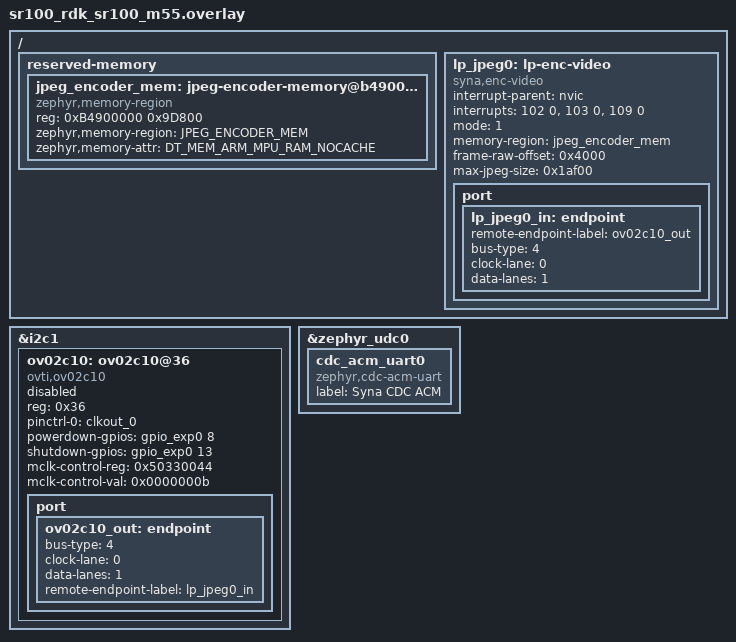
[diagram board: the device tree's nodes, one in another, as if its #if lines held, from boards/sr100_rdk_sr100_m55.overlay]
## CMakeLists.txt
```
cmake_minimum_required(VERSION 3.20.0)
find_package(Zephyr REQUIRED HINTS $ENV{ZEPHYR_BASE})
project(camera_usb_stream)

# Pulls in the Zephyr sample_usbd helper (sample_usbd.h/.c), reused verbatim
# from the SDK's mipi_capture_to_enc sample instead of hand-rolling USB
# device-stack bring-up.
include(${ZEPHYR_BASE}/samples/subsys/usb/common/common.cmake)

target_sources(app PRIVATE
	src/main.c
	src/usb_cdc_transport.c
)
```

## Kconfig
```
mainmenu "USB CDC Camera Streaming Lab (SR110 Lab C5)"

source "Kconfig.zephyr"

# Reuses Zephyr's shared "sample_usbd" helper Kconfig (device descriptors,
# VID/PID, etc.) - same mechanism the SDK's mipi_capture_to_enc sample uses.
source "samples/subsys/usb/common/Kconfig.sample_usbd"

config SAMPLE_USBD_PRODUCT
	default "SR110_Camera_Stream"

config SAMPLE_USBD_PID
	default 0x0009

menu "USB Camera Streaming Lab"

endmenu
```

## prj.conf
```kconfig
CONFIG_CONSOLE=y
CONFIG_PRINTK=y
CONFIG_LOG=y
CONFIG_LOG_MODE_IMMEDIATE=y
# Avoid Kconfig warnings from board defaults pulling in I2C shell options.
CONFIG_I2C_SHELL=n
CONFIG_FPU=y
CONFIG_I2C=y
CONFIG_GPIO=y
CONFIG_PINCTRL=y
CONFIG_VIDEO=y
CONFIG_VIDEO_SYNA_ENC=y
CONFIG_VIDEO_SYNA_MIPI=n
CONFIG_VIDEO_INIT_PRIORITY=90

# Two 128 KiB buffers + overhead (give headroom) - same as Lab C4.
CONFIG_VIDEO_BUFFER_POOL_HEAP_SIZE=524288

CONFIG_MAIN_STACK_SIZE=4096

# USB CDC ACM transport, reused from the SDK's mipi_capture_to_enc sample
# (its Kconfig wraps these under CONFIG_USB_TRANSPORT_CDC_ACM; this lab
# only ever needs CDC, so the symbols are set directly here instead of
# adding an unused mode-select option).
CONFIG_USB_DEVICE_STACK_NEXT=y
CONFIG_USBD_CDC_ACM_CLASS=y
CONFIG_CRC=y
CONFIG_SERIAL=y
CONFIG_UART_LINE_CTRL=y
CONFIG_UART_INTERRUPT_DRIVEN=y
```

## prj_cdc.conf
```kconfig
#
# USB CDC ACM transport tuning, reused verbatim from the SDK's
# mipi_capture_to_enc sample (samples/drivers/video/mipi_capture_to_enc/prj_cdc.conf).
#
# Include this with:
#   -DEXTRA_CONF_FILE=prj_cdc.conf
#

# USB device stack / UDC tuning
CONFIG_USBD_MAX_SPEED_FULL=y
CONFIG_UDC_DRIVER_HIGH_SPEED_SUPPORT_ENABLED=n
CONFIG_USBD_BOS_SUPPORT=n
CONFIG_USBD_VREQ_SUPPORT=n
CONFIG_UDC_BUF_POOL_SIZE=2048
CONFIG_USBD_MAX_UDC_MSG=8
CONFIG_USBD_MSG_SLAB_COUNT=8
CONFIG_USBD_HWINFO_DEVID_LENGTH=8

# USB threads can get tight with logging + DMA; keep some headroom.
CONFIG_USBD_THREAD_STACK_SIZE=2048
CONFIG_UDC_DWC2_STACK_SIZE=2048

# Quiet USB/UDC logs (avoid flooding UART during CDC transfers).
CONFIG_USBD_LOG_LEVEL_ERR=y
CONFIG_UDC_DRIVER_LOG_LEVEL_ERR=y
CONFIG_USBD_CDC_ACM_LOG_LEVEL_ERR=y
```

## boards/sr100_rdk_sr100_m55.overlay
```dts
#include <zephyr/dt-bindings/gpio/gpio.h>
#include <zephyr/dt-bindings/memory-attr/memory-attr-arm.h>

/*
 * JPEG encoder devicetree wiring, reused verbatim from Lab C4 / the SDK's
 * `enc` sample: reserved-memory region + lp_jpeg0 node + direct CSI
 * endpoint link to the ov02c10 sensor (bypasses video_syna0, see Lab C4 doc).
 */

/ {
	reserved-memory {
		#address-cells = <1>;
		#size-cells = <1>;
		ranges;

		jpeg_encoder_mem: jpeg-encoder-memory@b4900000 {
			compatible = "zephyr,memory-region", "mmio-sram";
			reg = <0xB4900000 0x9D800>; /* 0x4000 + 0x7e900 (960x540 RAW8) + 0x1af00 (max JPEG) */
			zephyr,memory-region = "JPEG_ENCODER_MEM";
			zephyr,memory-attr = <DT_MEM_ARM_MPU_RAM_NOCACHE>;
		};
	};

	lp_jpeg0: lp-enc-video {
		compatible = "syna,enc-video";
		status = "okay";
		interrupt-parent = <&nvic>;
		/*
		 * This JPEG encoder flow uses all three underlying IRQ lines:
		 * 102 = FRAME_PROCESSING_DONE, 103 = FMIN1_FRAME_STORED,
		 * 109 = c0 / status events.
		 */
		interrupts = <102 0>, <103 0>, <109 0>;
		interrupt-names = "frame-done", "fmin1-stored", "status";

		/*
		 * Build-time selectable mode (same convention as Lab C4).
		 *
		 * Define ENC_MEMORY_INPUT via DTS_EXTRA_CPPFLAGS to switch the
		 * encoder to reserved-memory input mode (static color-bar test
		 * pattern, no camera required) instead of the live sensor.
		 */
#ifdef ENC_MEMORY_INPUT
		mode = <1>; /* memory-input mode */
#else
		mode = <0>; /* live sensor mode (default) */
#endif

		/* JPEG encoder reserved memory for raw input and JPEG output buffers. */
		memory-region = <&jpeg_encoder_mem>;
		/* Reserve programmer area (SRSDK default is 0x4000). */
		frame-raw-offset = <0x4000>;

#ifdef ENC_MEMORY_INPUT
		/* Raw input (960x540 = 0x7E900 bytes) starts at frame-raw-offset. */
		max-jpeg-size = <0x1af00>;
#else
		max-jpeg-size = <0x20000>;
#endif

		port {
			lp_jpeg0_in: endpoint {
				remote-endpoint-label = "ov02c10_out";
				bus-type = <4>;
				clock-lane = <0>;
				data-lanes = <1>;
			};
		};

	};
};

&i2c1 {
	ov02c10: ov02c10@36 {
		compatible = "ovti,ov02c10";
		reg = <0x36>;
#ifdef ENC_MEMORY_INPUT
		status = "disabled";
#else
		status = "okay";
#endif

		pinctrl-0 = <&clkout_0>;
		pinctrl-names = "default";

		powerdown-gpios = <&gpio_exp0 8 GPIO_ACTIVE_HIGH>;
		shutdown-gpios = <&gpio_exp0 13 GPIO_ACTIVE_HIGH>;

		mclk-control-reg = <0x50330044>;
		mclk-control-val = <0x0000000b>;

		port {
			ov02c10_out: endpoint {
				bus-type = <4>;
				clock-lane = <0>;
				data-lanes = <1>;
				remote-endpoint-label = "lp_jpeg0_in";
			};
		};
	};
};

/*
 * USB CDC ACM virtual COM port, reused verbatim from the SDK's
 * mipi_capture_to_enc sample - kept in a separate node label so the JPEG
 * pipeline wiring above stays identical to Lab C4's overlay.
 */
&zephyr_udc0 {
	cdc_acm_uart0: cdc_acm_uart0 {
		compatible = "zephyr,cdc-acm-uart";
		label = "Syna CDC ACM";
	};
};
```

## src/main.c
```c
/*
 * Copyright (c) 2026 Synaptics Incorporated
 *
 * SPDX-License-Identifier: Apache-2.0
 *
 * Lab C5 - USB CDC real-time streaming.
 *
 * Base structure (devicetree wiring, encoder setup/buffer-queue helpers)
 * reused verbatim from Lab C4 / the SDK's `enc` sample. The single-shot
 * "capture one frame, dump via GDB" flow is replaced with a continuous
 * loop: dequeue a JPEG frame, send it over USB CDC ACM (transport code
 * reused verbatim from the SDK's mipi_capture_to_enc sample), re-enqueue
 * the buffer for the next frame, repeat.
 *
 * Unlike mipi_capture_to_enc (1920x1080 capture split into four 960x540
 * quadrants), this lab keeps this curriculum's established single-frame
 * 480x270 resolution (same as Lab C1-C4) - no quadrant splitting, no XSPI
 * storage, CDC only (no UVC). See the lab doc for why.
 */

#include <errno.h>
#include <stdint.h>
#include <string.h>

#include <zephyr/cache.h>
#include <zephyr/device.h>
#include <zephyr/devicetree.h>
#include <zephyr/drivers/video.h>
#include <zephyr/kernel.h>
#include <zephyr/logging/log.h>
#include <zephyr/sys/barrier.h>
#include <zephyr/sys/util.h>
#include <zephyr/video/video.h>

#include "usb_cdc_transport.h"

LOG_MODULE_REGISTER(usb_stream_sample, LOG_LEVEL_INF);

static inline int64_t app_elapsed_ms(int64_t start_ms)
{
	return k_uptime_get() - start_ms;
}

#define ENC_NODE DT_NODELABEL(lp_jpeg0)

#if !DT_NODE_EXISTS(ENC_NODE)
#error "No lp_jpeg0 devicetree node found"
#endif

#if !DT_NODE_HAS_COMPAT(ENC_NODE, syna_enc_video)
#error "lp_jpeg0 must use compatible = \"syna,enc-video\""
#endif

#define APP_MODE_SENSOR_TO_MEMORY 0U
#define APP_MODE_MEMORY_INPUT 1U
#define APP_PIPELINE_MODE DT_PROP_OR(ENC_NODE, mode, APP_MODE_SENSOR_TO_MEMORY)

#define APP_NUM_BUFS 2U
#define APP_JPEG_BUF_ALIGN 64U
#define APP_MAX_JPEG_BYTES (128U * 1024U)
#define APP_DEQUEUE_TIMEOUT K_SECONDS(5)

#define APP_LIVE_WIDTH 480U
#define APP_LIVE_HEIGHT 270U

#define APP_MEMORY_INPUT_WIDTH 960U
#define APP_MEMORY_INPUT_HEIGHT 540U
#define APP_MEMORY_INPUT_RAW_SIZE ((size_t)APP_MEMORY_INPUT_WIDTH * (size_t)APP_MEMORY_INPUT_HEIGHT)

/* mode=1 has no live camera driving new frames, so just re-send the same
 * static test pattern this many times before stopping (enough for the host
 * viewer script to show something without streaming forever).
 */
#define APP_MEMORY_MODE_FRAME_COUNT 30U

#define APP_MEM_REGION_PRESENT DT_NODE_HAS_PROP(ENC_NODE, memory_region)
BUILD_ASSERT(APP_MEM_REGION_PRESENT,
	     "JPEG encoder sample requires a memory-region devicetree phandle");
#if APP_MEM_REGION_PRESENT
#define APP_MEM_NODE DT_PHANDLE(ENC_NODE, memory_region)
#define APP_MEM_BASE ((uintptr_t)DT_REG_ADDR(APP_MEM_NODE))
#define APP_MEM_SIZE ((size_t)DT_REG_SIZE(APP_MEM_NODE))
#else
#define APP_MEM_BASE ((uintptr_t)0U)
#define APP_MEM_SIZE 0U
#endif

#define APP_RAW_OFFSET ((size_t)DT_PROP_OR(ENC_NODE, frame_raw_offset, 0))

static uint8_t app_jpeg_buf_mem[APP_NUM_BUFS][APP_MAX_JPEG_BYTES] __aligned(APP_JPEG_BUF_ALIGN);
static struct video_buffer app_jpeg_vbufs[APP_NUM_BUFS];

#if IS_ENABLED(CONFIG_CACHE_MANAGEMENT) && IS_ENABLED(CONFIG_DCACHE)
static void enc_mem_flush(uintptr_t addr, size_t size)
{
	int ret;

	if (size == 0U) {
		return;
	}

	ret = sys_cache_data_flush_range((void *)addr, size);
	if (ret != 0) {
		LOG_WRN("Encoder memory cache flush failed ret=%d addr=%p size=%u",
			ret, (void *)addr, (unsigned int)size);
	}
	barrier_dsync_fence_full();
}
#else
static void enc_mem_flush(uintptr_t addr, size_t size)
{
	ARG_UNUSED(addr);
	ARG_UNUSED(size);
}
#endif

static const char *mode_name(uint32_t mode)
{
	if (mode == APP_MODE_MEMORY_INPUT) {
		return "enc-memory-input";
	}

	return "live-to-memory";
}

/* Drain any returned buffers after stopping the stream. */
static void drain_buffers(const struct device *dev)
{
	struct video_buffer *vbuf = NULL;

	while ((video_dequeue(dev, &vbuf, K_NO_WAIT) == 0) && (vbuf != NULL)) {
		vbuf->bytesused = 0U;
	}
}

/*
 * Configure the JPEG output format.
 *
 * The negotiated `jpeg_fmt->size` is the required output-buffer capacity.
 * The actual JPEG size is returned later in `video_buffer.bytesused`.
 */
static int enc_configure(const struct device *enc,
			 struct video_format *jpeg_fmt,
			 uint32_t width,
			 uint32_t height)
{
	int ret;

	*jpeg_fmt = (struct video_format) {
		.type = VIDEO_BUF_TYPE_OUTPUT,
		.pixelformat = VIDEO_PIX_FMT_JPEG,
		.width = width,
		.height = height,
	};

	ret = video_set_format(enc, jpeg_fmt);
	LOG_INF("enc video_set_format ret=%d capacity=%u pitch=%u (%ux%u)",
		ret, jpeg_fmt->size, jpeg_fmt->pitch,
		jpeg_fmt->width, jpeg_fmt->height);
	return ret;
}

/* Allocate and enqueue destination buffers for JPEG output. */
static int jpeg_buffers_queue(const struct device *enc,
			      const struct video_format *jpeg_fmt)
{
	struct video_caps caps = {
		.type = VIDEO_BUF_TYPE_OUTPUT,
	};
	size_t align = APP_JPEG_BUF_ALIGN;
	int ret;

	if ((jpeg_fmt == NULL) || (jpeg_fmt->size > APP_MAX_JPEG_BYTES)) {
		LOG_ERR("JPEG buffer pool too small: required capacity=%u max=%u",
			jpeg_fmt != NULL ? jpeg_fmt->size : 0U,
			(unsigned int)APP_MAX_JPEG_BYTES);
		return -EINVAL;
	}

	ret = video_get_caps(enc, &caps);
	LOG_INF("enc video_get_caps ret=%d min_vbuf=%u align=%zu",
		ret, caps.min_vbuf_count, caps.buf_align);
	if (ret != 0) {
		return ret;
	}

	if (APP_NUM_BUFS < caps.min_vbuf_count) {
		LOG_ERR("APP_NUM_BUFS too small: available=%u required(min_vbuf_count)=%u",
			(unsigned int)APP_NUM_BUFS, caps.min_vbuf_count);
		return -EINVAL;
	}

	if (caps.buf_align != 0U) {
		align = caps.buf_align;
	}

	if (align > APP_JPEG_BUF_ALIGN) {
		LOG_ERR("JPEG buffer alignment too small: required=%zu available=%u",
			align, (unsigned int)APP_JPEG_BUF_ALIGN);
		return -EINVAL;
	}

	for (size_t i = 0; i < APP_NUM_BUFS; i++) {
		struct video_buffer *vbuf = &app_jpeg_vbufs[i];
		uint16_t imported_idx;

		memset(vbuf, 0, sizeof(*vbuf));
		vbuf->type = VIDEO_BUF_TYPE_OUTPUT;
		vbuf->buffer = app_jpeg_buf_mem[i];
		vbuf->size = APP_MAX_JPEG_BYTES;

		ret = video_import_buffer(vbuf->buffer, vbuf->size, &imported_idx);
		if (ret != 0) {
			LOG_ERR("enc video_import_buffer[%u] failed: %d", (unsigned int)i, ret);
			return ret;
		}
		vbuf->index = imported_idx;

		LOG_INF("enc app_buf[%u] addr=%p size=%u align=%zu",
			(unsigned int)i, vbuf->buffer, (unsigned int)vbuf->size, align);

		ret = video_enqueue(enc, vbuf);
		LOG_INF("enc video_enqueue[%u] ret=%d", (unsigned int)i, ret);
		if (ret != 0) {
			return ret;
		}
	}

	return 0;
}

/* Static reserved-memory input frame generation (mode=1 only) */

static uint8_t bayer_from_rgb(uint16_t x, uint16_t y, uint8_t red,
			      uint8_t green, uint8_t blue)
{
	if (((y & 1U) == 0U) && ((x & 1U) == 0U)) {
		return blue;
	}

	if (((y & 1U) == 1U) && ((x & 1U) == 1U)) {
		return red;
	}

	return green;
}

static void fill_bayer_pattern(uint8_t *dst, uint16_t width, uint16_t height)
{
	static const uint8_t color_bars[][3] = {
		{ 0x00, 0x00, 0x00 }, /* black */
		{ 0x00, 0x00, 0xff }, /* blue */
		{ 0x00, 0xff, 0xff }, /* cyan */
		{ 0x00, 0xff, 0x00 }, /* green */
		{ 0xff, 0x00, 0xff }, /* magenta */
		{ 0xff, 0x00, 0x00 }, /* red */
		{ 0xff, 0xff, 0x00 }, /* yellow */
		{ 0xff, 0xff, 0xff }, /* white */
	};
	const uint16_t bar_count = ARRAY_SIZE(color_bars);

	for (uint16_t y = 0; y < height; y++) {
		for (uint16_t x = 0; x < width; x++) {
			uint16_t bar = (uint16_t)(((uint32_t)x * bar_count) /
						  MAX(width, (uint16_t)1U));
			uint8_t red;
			uint8_t green;
			uint8_t blue;

			if (bar >= bar_count) {
				bar = bar_count - 1U;
			}

			red = color_bars[bar][0];
			green = color_bars[bar][1];
			blue = color_bars[bar][2];

			if ((y > (height * 3U) / 4U) &&
			    (((x / 16U) & 1U) != ((y / 16U) & 1U))) {
				red >>= 1;
				green >>= 1;
				blue >>= 1;
			}

			dst[(size_t)y * width + x] =
				bayer_from_rgb(x, y, red, green, blue);
		}
	}
}

/* Seed the raw reserved-memory input frame into reserved memory based on DTS offsets. */
static int seed_memory_frame(void)
{
	uint8_t *raw;
	int64_t seed_start_ms = k_uptime_get();

	if ((APP_MEM_BASE == 0U) || (APP_MEM_SIZE == 0U)) {
		LOG_ERR("Encoder memory base/size missing in DTS");
		return -EINVAL;
	}

	if ((APP_MEMORY_INPUT_RAW_SIZE > APP_MEM_SIZE) ||
	    (APP_RAW_OFFSET > (APP_MEM_SIZE - APP_MEMORY_INPUT_RAW_SIZE))) {
		LOG_ERR("reserved-memory raw source buffer does not fit reserved memory");
		return -ENOMEM;
	}

	raw = (uint8_t *)(uintptr_t)(APP_MEM_BASE + APP_RAW_OFFSET);
	fill_bayer_pattern(raw, APP_MEMORY_INPUT_WIDTH, APP_MEMORY_INPUT_HEIGHT);
	enc_mem_flush((uintptr_t)raw, APP_MEMORY_INPUT_RAW_SIZE);

	LOG_INF("Seeded encoder-memory raw Bayer color-bar pattern at %p size=%u (%ux%u)",
		raw, (unsigned int)APP_MEMORY_INPUT_RAW_SIZE,
		APP_MEMORY_INPUT_WIDTH, APP_MEMORY_INPUT_HEIGHT);
	LOG_INF("Input frame seeded in encoder RAM in %lld ms",
		(long long)app_elapsed_ms(seed_start_ms));
	return 0;
}

/* Stop streams and return any queued buffers back to the app. */
static void cleanup_capture(const struct device *enc,
			    bool jpeg_buffers_queued,
			    bool enc_started)
{
	if (enc_started) {
		(void)video_stream_stop(enc, VIDEO_BUF_TYPE_OUTPUT);
	} else if (jpeg_buffers_queued) {
		(void)video_flush(enc, true);
	}

	if (jpeg_buffers_queued) {
		drain_buffers(enc);
	}
}

/*
 * Continuous capture -> encode -> USB CDC send loop.
 *
 * frame_limit == 0 means "stream forever" (live sensor mode); a non-zero
 * value stops after that many frames (used for mode=1's static test
 * pattern, which has nothing new to show after a few repeats).
 */
static int stream_loop(const struct device *enc, uint32_t mode, uint32_t frame_limit)
{
	struct cdc_transport_ctx cdc_ctx = { 0 };
	uint16_t frame_id = 0U;
	int ret;

	ret = cdc_transport_init(&cdc_ctx);
	if (ret != 0) {
		LOG_ERR("USB CDC init failed: %d", ret);
		return ret;
	}

	LOG_INF("USB CDC ready; waiting for host DTR (connect + open the PC viewer)...");
	ret = cdc_transport_wait_dtr(&cdc_ctx, K_FOREVER);
	if (ret != 0) {
		LOG_ERR("USB CDC wait DTR failed: %d", ret);
		return ret;
	}
	LOG_INF("Host DTR set - streaming started (mode=%s)", mode_name(mode));

	while (true) {
		struct video_buffer *out = NULL;

		ret = video_dequeue(enc, &out, APP_DEQUEUE_TIMEOUT);
		if (ret != 0) {
			LOG_ERR("video_dequeue failed ret=%d", ret);
			return ret;
		}

		if (out->bytesused != 0U) {
#if IS_ENABLED(CONFIG_CACHE_MANAGEMENT) && IS_ENABLED(CONFIG_DCACHE)
			(void)sys_cache_data_flush_range(out->buffer, out->bytesused);
#endif
			ret = cdc_transport_send_jpeg(&cdc_ctx, frame_id, out->buffer,
						      out->bytesused);
			if (ret != 0) {
				/*
				 * Host likely closed the port (e.g. Ctrl+C on the
				 * viewer script). Stop the stream instead of
				 * spinning - re-run the app to reconnect.
				 */
				LOG_WRN("CDC send failed ret=%d (host disconnected?) - stopping",
					ret);
				(void)video_enqueue(enc, out);
				return ret;
			}

			if ((frame_id % 30U) == 0U) {
				LOG_INF("Streamed frame %u (%u bytes)",
					(unsigned int)frame_id,
					(unsigned int)out->bytesused);
			}
		}

		frame_id++;

		/* Re-queue the same buffer so the encoder can fill it again. */
		ret = video_enqueue(enc, out);
		if (ret != 0) {
			LOG_ERR("video_enqueue (re-queue) failed ret=%d", ret);
			return ret;
		}

		if ((frame_limit != 0U) && (frame_id >= frame_limit)) {
			LOG_INF("Reached frame_limit=%u, stopping stream", frame_limit);
			return 0;
		}
	}
}

/* Run mode 0: live sensor streamed continuously over USB CDC. */
static int run_live_mode(const struct device *enc)
{
	struct video_format jpeg_fmt;
	bool jpeg_buffers_queued = false;
	bool enc_started = false;
	int ret;

	ret = enc_configure(enc, &jpeg_fmt, APP_LIVE_WIDTH, APP_LIVE_HEIGHT);
	if (ret != 0) {
		LOG_ERR("JPEG encoder format configuration failed ret=%d", ret);
		goto out;
	}

	ret = jpeg_buffers_queue(enc, &jpeg_fmt);
	if (ret != 0) {
		LOG_ERR("failed to prepare JPEG encoder buffers ret=%d", ret);
		goto out;
	}
	jpeg_buffers_queued = true;

	ret = video_stream_start(enc, VIDEO_BUF_TYPE_OUTPUT);
	LOG_INF("enc video_stream_start ret=%d", ret);
	if (ret != 0) {
		LOG_ERR("JPEG encoder stream start failed ret=%d", ret);
		goto out;
	}
	enc_started = true;

	ret = stream_loop(enc, APP_MODE_SENSOR_TO_MEMORY, 0U);

out:
	cleanup_capture(enc, jpeg_buffers_queued, enc_started);
	return ret;
}

/* Run mode 1: reserved-memory test pattern, repeated a fixed number of times. */
static int run_memory_mode(const struct device *enc)
{
	struct video_format jpeg_fmt;
	bool jpeg_buffers_queued = false;
	bool enc_started = false;
	int ret;

	ret = enc_configure(enc, &jpeg_fmt, APP_MEMORY_INPUT_WIDTH, APP_MEMORY_INPUT_HEIGHT);
	if (ret != 0) {
		LOG_ERR("JPEG encoder format configuration failed ret=%d", ret);
		return ret;
	}

	ret = seed_memory_frame();
	if (ret != 0) {
		LOG_ERR("failed to seed reserved-memory input frame ret=%d", ret);
		return ret;
	}

	ret = jpeg_buffers_queue(enc, &jpeg_fmt);
	if (ret != 0) {
		LOG_ERR("failed to prepare JPEG encoder buffers ret=%d", ret);
		goto out;
	}
	jpeg_buffers_queued = true;

	ret = video_stream_start(enc, VIDEO_BUF_TYPE_OUTPUT);
	LOG_INF("enc video_stream_start ret=%d", ret);
	if (ret != 0) {
		LOG_ERR("JPEG encoder stream start failed ret=%d", ret);
		goto out;
	}
	enc_started = true;

	ret = stream_loop(enc, APP_MODE_MEMORY_INPUT, APP_MEMORY_MODE_FRAME_COUNT);

out:
	cleanup_capture(enc, jpeg_buffers_queued, enc_started);
	return ret;
}

int main(void)
{
	const struct device *enc = DEVICE_DT_GET(ENC_NODE);
	uint32_t mode = APP_PIPELINE_MODE;
	int64_t app_start_ms = k_uptime_get();
	int ret;

	LOG_INF("USB CDC streaming lab start (%s, mode=%u)",
		mode_name(mode), (unsigned int)mode);

	if (!device_is_ready(enc)) {
		LOG_ERR("JPEG encoder device not ready");
		return -ENODEV;
	}

	if (mode == APP_MODE_MEMORY_INPUT) {
		ret = run_memory_mode(enc);
	} else if (mode == APP_MODE_SENSOR_TO_MEMORY) {
		ret = run_live_mode(enc);
	} else {
		LOG_ERR("unsupported sample mode %u", (unsigned int)mode);
		return -EINVAL;
	}

	LOG_INF("USB CDC streaming lab finished ret=%d after %lld ms",
		ret, (long long)app_elapsed_ms(app_start_ms));
	return ret;
}
```

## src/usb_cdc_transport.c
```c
/*
 * Copyright (c) 2026 Synaptics Incorporated
 *
 * SPDX-License-Identifier: Apache-2.0
 *
 * Reused verbatim from the SDK's mipi_capture_to_enc sample
 * (samples/drivers/video/mipi_capture_to_enc/src/usb_cdc_transport.c).
 * Not FHD/quadrant-specific - this file already sends one arbitrary-size
 * JPEG buffer per call, so Lab C5 (single 480x270 frame per call) needed
 * no changes here at all.
 */

#include <errno.h>
#include <stddef.h>
#include <stdint.h>
#include <string.h>

#include <zephyr/device.h>
#include <zephyr/drivers/uart.h>
#include <zephyr/kernel.h>
#include <zephyr/sys/byteorder.h>
#include <zephyr/sys/crc.h>
#include <zephyr/sys/time_units.h>
#include <zephyr/usb/usbd.h>

#include <sample_usbd.h>

#include "usb_cdc_transport.h"

/* Simple framing for host-side parsing. */
#define CDC_STREAM_MAGIC UINT32_C(0x51425553) /* "QBUS" */
#define CDC_STREAM_VERSION 1U
#define CDC_STREAM_TX_TIMEOUT K_SECONDS(10)

#define CDC_STREAM_HDR_SIZE 16U

BUILD_ASSERT(CDC_STREAM_HDR_SIZE == (4U + 2U + 1U + 1U + 4U + 4U), "cdc header size mismatch");

static void cdc_irq_handler(const struct device *dev, void *user_data)
{
	struct cdc_transport_ctx *ctx = user_data;

	if ((dev == NULL) || (ctx == NULL)) {
		return;
	}

	while (uart_irq_update(dev) && uart_irq_is_pending(dev)) {
		if (uart_irq_tx_ready(dev)) {
			if (ctx->tx_remaining == 0U) {
				uart_irq_tx_disable(dev);
				k_sem_give(&ctx->tx_done_sem);
				continue;
			}

			int wrote = uart_fifo_fill(dev, ctx->tx_ptr, ctx->tx_remaining);

			if (wrote > 0) {
				ctx->tx_ptr += (size_t)wrote;
				ctx->tx_remaining -= (size_t)wrote;
			} else {
				/* Nothing accepted right now; exit ISR loop. */
				break;
			}
		} else {
			/* No TX work; exit ISR loop. */
			break;
		}
	}
}

static int cdc_send_blocking(struct cdc_transport_ctx *ctx, const uint8_t *data, size_t len)
{
	unsigned int key;

	if ((ctx == NULL) || (ctx->cdc_dev == NULL) || (data == NULL) || (len == 0U)) {
		return -EINVAL;
	}

	/* Ensure the ISR cannot observe partially-updated tx_* state. */
	key = irq_lock();
	uart_irq_tx_disable(ctx->cdc_dev);

	ctx->tx_ptr = data;
	ctx->tx_remaining = len;
	irq_unlock(key);

	k_sem_reset(&ctx->tx_done_sem);

	/* Start TX; ISR will drain the buffer and signal completion. */
	uart_irq_tx_enable(ctx->cdc_dev);
	int ret = k_sem_take(&ctx->tx_done_sem, CDC_STREAM_TX_TIMEOUT);
	if (ret != 0) {
		uart_irq_tx_disable(ctx->cdc_dev);
		ctx->tx_ptr = NULL;
		ctx->tx_remaining = 0U;
	}
	return ret;
}

int cdc_transport_init(struct cdc_transport_ctx *ctx)
{
	int ret;

	if (ctx == NULL) {
		return -EINVAL;
	}

	if (ctx->usbd_ctx != NULL) {
		return 0;
	}

	k_sem_init(&ctx->tx_done_sem, 0, 1);

	/*
	 * Use a polling-based DTR wait to avoid global state in the USBD message
	 * callback path (sample_usbd_init_device() does not provide a user_data).
	 */
	ctx->usbd_ctx = sample_usbd_init_device(NULL);
	if (ctx->usbd_ctx == NULL) {
		return -ENODEV;
	}

	/* If VBUS detection is not supported, enable right away. */
	if (!usbd_can_detect_vbus(ctx->usbd_ctx)) {
		ret = usbd_enable(ctx->usbd_ctx);
		if (ret != 0) {
			(void)usbd_shutdown(ctx->usbd_ctx);
			ctx->usbd_ctx = NULL;
			return ret;
		}
	}

	ctx->cdc_dev = DEVICE_DT_GET(DT_NODELABEL(cdc_acm_uart0));
	if (!device_is_ready(ctx->cdc_dev)) {
		return -ENODEV;
	}

	ret = uart_irq_callback_user_data_set(ctx->cdc_dev, cdc_irq_handler, ctx);
	if (ret != 0) {
		return ret;
	}
	uart_irq_tx_disable(ctx->cdc_dev);

	return 0;
}

int cdc_transport_wait_dtr(struct cdc_transport_ctx *ctx, k_timeout_t timeout)
{
	uint32_t dtr = 0U;

	if ((ctx == NULL) || (ctx->cdc_dev == NULL)) {
		return -ENODEV;
	}

	if (uart_line_ctrl_get(ctx->cdc_dev, UART_LINE_CTRL_DTR, &dtr) == 0 && dtr != 0U) {
		return 0;
	}

	if (timeout.ticks == K_NO_WAIT.ticks) {
		return -EAGAIN;
	}

	if (timeout.ticks == K_FOREVER.ticks) {
		while (true) {
			k_sleep(K_MSEC(20));
			if (uart_line_ctrl_get(ctx->cdc_dev, UART_LINE_CTRL_DTR, &dtr) == 0 &&
			    dtr != 0U) {
				return 0;
			}
		}
	}

	int64_t deadline_ms = (int64_t)k_uptime_get() + (int64_t)k_ticks_to_ms_floor64(timeout.ticks);

	while ((int64_t)k_uptime_get() < deadline_ms) {
		k_sleep(K_MSEC(20));
		if (uart_line_ctrl_get(ctx->cdc_dev, UART_LINE_CTRL_DTR, &dtr) == 0 && dtr != 0U) {
			return 0;
		}
	}

	return -EAGAIN;
}

int cdc_transport_send_jpeg(struct cdc_transport_ctx *ctx, uint16_t image_id,
			    const uint8_t *jpeg, size_t jpeg_len)
{
	uint8_t hdr[CDC_STREAM_HDR_SIZE];
	uint32_t dtr = 0U;
	int ret;

	if ((ctx == NULL) || (jpeg == NULL) || (jpeg_len == 0U)) {
		return -EINVAL;
	}

	if (image_id > UINT8_MAX) {
		return -EINVAL;
	}

	if (jpeg_len > UINT32_MAX) {
		return -EOVERFLOW;
	}

	/* Avoid long TX timeouts when the host hasn't asserted DTR. */
	if ((ctx->cdc_dev == NULL) ||
	    (uart_line_ctrl_get(ctx->cdc_dev, UART_LINE_CTRL_DTR, &dtr) != 0) || (dtr == 0U)) {
		return -ENOTCONN;
	}

	memset(hdr, 0, sizeof(hdr));
	sys_put_le32(CDC_STREAM_MAGIC, &hdr[0]);
	sys_put_le16((uint16_t)CDC_STREAM_VERSION, &hdr[4]);
	hdr[6] = (uint8_t)image_id;
	hdr[7] = 0U; /* flags */
	sys_put_le32((uint32_t)jpeg_len, &hdr[8]);
	sys_put_le32(crc32_ieee(jpeg, jpeg_len), &hdr[12]);

	ret = cdc_send_blocking(ctx, hdr, sizeof(hdr));
	if (ret != 0) {
		return ret;
	}

	return cdc_send_blocking(ctx, jpeg, jpeg_len);
}
```

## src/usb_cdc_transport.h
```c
/*
 * Copyright (c) 2026 Synaptics Incorporated
 *
 * SPDX-License-Identifier: Apache-2.0
 *
 * Reused verbatim from the SDK's mipi_capture_to_enc sample
 * (samples/drivers/video/mipi_capture_to_enc/src/usb_cdc_transport.h).
 */

#ifndef LAB_C5_USB_CDC_TRANSPORT_H_
#define LAB_C5_USB_CDC_TRANSPORT_H_

#include <stddef.h>
#include <stdint.h>

#include <zephyr/device.h>
#include <zephyr/kernel.h>

struct usbd_context;

struct cdc_transport_ctx {
	struct usbd_context *usbd_ctx;
	const struct device *cdc_dev;
	struct k_sem tx_done_sem;
	const uint8_t *tx_ptr;
	size_t tx_remaining;
};

int cdc_transport_init(struct cdc_transport_ctx *ctx);
int cdc_transport_wait_dtr(struct cdc_transport_ctx *ctx, k_timeout_t timeout);
int cdc_transport_send_jpeg(struct cdc_transport_ctx *ctx, uint16_t image_id,
			    const uint8_t *jpeg, size_t jpeg_len);

#endif /* LAB_C5_USB_CDC_TRANSPORT_H_ */
```
